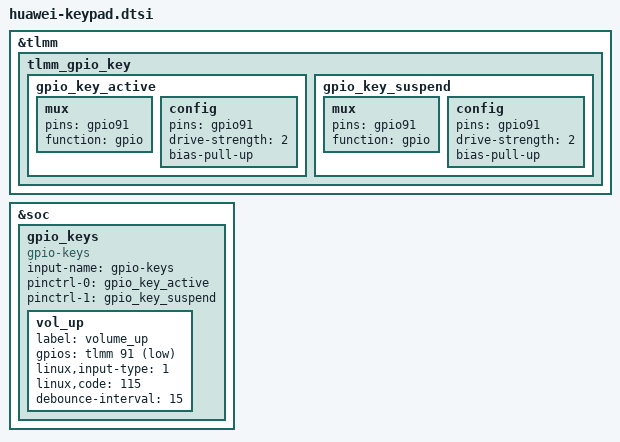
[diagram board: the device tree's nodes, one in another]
&tlmm {
	tlmm_gpio_key {
			gpio_key_active: gpio_key_active {
				mux {
					pins = "gpio91";
					function = "gpio";
				};

				config {
					pins = "gpio91";
					drive-strength = <2>;
					bias-pull-up;
				};
			};

			gpio_key_suspend: gpio_key_suspend {
				mux {
					pins = "gpio91";
					function = "gpio";
				};

				config {
					pins = "gpio91";
					drive-strength = <2>;
					bias-pull-up;
				};
			};
		};
	};
	
&soc {
		gpio_keys {
		compatible = "gpio-keys";
		input-name = "gpio-keys";
		pinctrl-names = "tlmm_gpio_key_active","tlmm_gpio_key_suspend";
		pinctrl-0 = <&gpio_key_active>;
		pinctrl-1 = <&gpio_key_suspend>;

		vol_up {
			label = "volume_up";
			gpios = <&tlmm 91 0x1>;
			linux,input-type = <1>;
			linux,code = <115>;
			debounce-interval = <15>;
		};
	};
};
